# aes register map
Vendor: Texas Instruments
Peripheral module from a debugger description file (folder cc32).
Registers are 32-bit, access not given, no defined reset value unless marked. A register's access mark holds for its fields unless they carry their own. Offsets are as the file gives them; lines under a group give offsets from that group; [hi:lo] are bit positions; {n}, {i} and the like mark numbered series; 'fields as' and 'values as' point back to an identical list; <NAME> marks a mode.

## aes
0x00 KEY2_6 — XTS second key / CBC-MAC third key
0x04 KEY2_7 — XTS second key (MSW for 256-bit key) / CBC-MAC third key (MSW)
0x08 KEY2_4 — XTS / CCM second key / CBC-MAC third key (LSW)
0x0C KEY2_5 — XTS second key (MSW for 192-bit key) / CBC-MAC third key
0x10 KEY2_2 — XTS / CCM / CBC-MAC second key / Hash Key input
0x14 KEY2_3 — XTS second key (MSW for 128-bit key) + CCM/CBC-MAC second key (MSW) / Hash Key input (MSW)
0x18 KEY2_0 — XTS / CCM / CBC-MAC second key (LSW) / Hash Key input (LSW)
0x1C KEY2_1 — XTS / CCM / CBC-MAC second key / Hash Key input
0x20 KEY1_6 — Key (LSW for 256-bit key)
0x24 KEY1_7 — Key (MSW for 256-bit key)
0x28 KEY1_4 — Key (LSW for 192-bit key)
0x2C KEY1_5 — Key (MSW for 192-bit key)
0x30 KEY1_2 — Key
0x34 KEY1_3 — Key (MSW for 128-bit key)
0x38 KEY1_0 — Key (LSW for 128-bit key)
0x3C KEY1_1 — Key
0x40 IV_IN_0 — Initialization Vector input (LSW)
0x44 IV_IN_1 — Initialization vector input
0x48 IV_IN_2 — Initialization vector input
0x4C IV_IN_3 — Initialization Vector input (MSW)
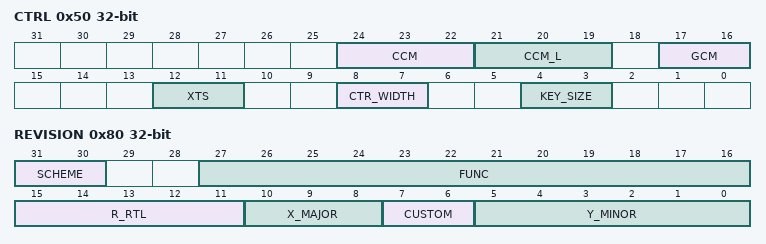
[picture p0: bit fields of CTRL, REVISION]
0x50 CTRL rw — register determines the mode of operation of the AES Engine
  [24:22] CCM — Defines M? that indicated the length of the authentication field for CCM operations; the authentication field length equals two times (the value of CCM-M plus one). Note that the AES Engine always returns a 128-bit authentication field@@ of which the M least significant bytes are valid. All values are supported.
  [21:19] CCM_L — Defines L? that indicated the width of the length field for CCM operations; the length field in bytes equals the value of CMM-L plus one. Supported values for L are (programmed value): 2 (1)@@ 4 (3) and 8 (7).
  [17:16] GCM — AES-GCM mode is selected.this is a combined mode@@ using the Galois field multiplier GF(2^128) for authentication and AES-CTR mode for encryption@@ the bits specify the GCM mode. 0x0 No operation 0x1 GHASH with H loaded and Y0-encrypted forced to zero 0x2 GHASH with H loaded and Y0-encrypted calculated internally 0x3 Autonomous GHASH (both H and Y0-encrypted calculated internally)
  [12:11] XTS — AES-XTS operation is selected; the bits specify the XTS mode.01 = Previous/intermediate tweak value and j loaded (value is loaded via IV@@ j is loaded via the AAD length register) 0x0 No operation 0x1 Previous/intermediate tweak value and j loaded (value is loaded via IV@@ j is loaded via the AAD length register) 0x2 Key2@@ i and j loaded (i is loaded via IV@@ j is loaded via the AAD length register) 0x3 Key2 and i loaded@@ j=0 (i is loaded via IV)
  [8:7] CTR_WIDTH — Specifies the counter width for AES-CTR mode 0x0 Counter is 32 bits 0x1 Counter is 64 bits 0x2 Counter is 128 bits 0x3 Counter is 192 bits
  [4:3] KEY_SIZE — key size 0x0 reserved 0x1 Key is 128 bits. 0x2 Key is 192 bits 0x3 Key is 256
0x54 C_LENGTH_0 — Crypto data length registers (LSW and MSW) store the cryptographic data length in bytes for all modes. Once processing with this context is started@@ this length decrements to zero. Data lengths up to (2^61 1) bytes are allowed. For GCM@@ any value up to 2^36 - 32 bytes can be used. This is because a 32-bit counter mode is used; the maximum number of 128-bit blocks is 2^32 2@@ resulting in a maximum number of bytes of 2^36 - 32. A write to this register triggers the engine to start using this context. This is valid for all modes except GCM and CCM. Note that for the combined modes@@ this length does not include the authentication only data; the authentication length is specified in the AES_AUTH_LENGTH register below. All modes must have a length > 0. For the combined modes@@ it is allowed to have one of the lengths equal to zero. For the basic encryption modes (ECB/CBC/CTR/ICM/CFB128) it is allowed to program zero to the length field; in that case the length is assumed infinite. All data must be byte (8-bit) aligned; bit aligned data streams are not supported by the AES Engine. For a Host read operation@@ these registers return all-zeroes.
0x58 C_LENGTH_1 rw — Crypto data length registers (LSW and MSW) store the cryptographic data length in bytes for all modes. Once processing with this context is started@@ this length decrements to zero. Data lengths up to (2^61 1) bytes are allowed. For GCM@@ any value up to 2^36 - 32 bytes can be used. This is because a 32-bit counter mode is used; the maximum number of 128-bit blocks is 2^32 2@@ resulting in a maximum number of bytes of 2^36 - 32. A write to this register triggers the engine to start using this context. This is valid for all modes except GCM and CCM. Note that for the combined modes@@ this length does not include the authentication only data; the authentication length is specified in the AES_AUTH_LENGTH register below. All modes must have a length > 0. For the combined modes@@ it is allowed to have one of the lengths equal to zero. For the basic encryption modes (ECB/CBC/CTR/ICM/CFB128) it is allowed to program zero to the length field; in that case the length is assumed infinite. All data must be byte (8-bit) aligned; bit aligned data streams are not supported by the AES Engine. For a Host read operation@@ these registers return all-zeroes.
  [28:0] LENGTH — Data length (MSW) length registers (LSW and MSW) store the cryptographic data length in bytes for all modes. Once processing with this context is started@@ this length decrements to zero. Data lengths up to (2^61 1) bytes are allowed. For GCM@@ any value up to 2^36 - 32 bytes can be used. This is because a 32-bit counter mode is used; the maximum number of 128-bit blocks is 2^32 2@@ resulting in a maximum number of bytes of 2^36 - 32. A write to this register triggers the engine to start using this context. This is valid for all modes except GCM and CCM. Note that for the combined modes@@ this length does not include the authentication only data; the authentication length is specified in the AES_AUTH_LENGTH register below. All modes must have a length > 0. For the combined modes@@ it is allowed to have one of the lengths equal to zero. For the basic encryption modes (ECB/CBC/CTR/ICM/CFB128) it is allowed to program zero to the length field; in that case the length is assumed infinite. All data must be byte (8-bit) aligned; bit aligned data streams are not supported by the AES Engine. For a Host read operation@@ these registers return all-zeroes.
0x5C AUTH_LENGTH — AAD data length. The authentication length register store the authentication data length in bytes for combined modes only (GCM or CCM) Supported AAD-lengths for CCM are from 0 to (2^16 - 2^8) bytes. For GCM any value up to (2^32 - 1) bytes can be used. Once processing with this context is started@@ this length decrements to zero. A write to this register triggers the engine to start using this context for GCM and CCM. For XTS this register is optionally used to load j. Loading of j is only required if j != 0. j is a 28-bit value and must be written to bits [31-4] of this register. j represents the sequential number of the 128-bit block inside the data unit. For the first block in a unit@@ this value is zero. It is not required to provide a j for each new data block within a unit. Note that it is possible to start with a j unequal to zero; refer to Table 4 for more details. For a Host read operation@@ these registers return all-zeroes.
0x60 DATA_IN_0 — Data register to read and write plaintext/ciphertext (MSW)
0x64 DATA_IN_1 — Data register to read and write plaintext/ciphertext
0x68 DATA_IN_2 — Data register to read and write plaintext/ciphertext
0x6C DATA_IN_3 — Data register to read and write plaintext/ciphertext (LSW)
{0x70+4i} TAG_OUT_{i} (i=0..3)
0x80 REVISION rw — Register AES_REVISION
  [31:30] SCHEME
  [27:16] FUNC — Function indicates a software compatible module family. If there is no level of software compatibility a new Func number (and hence REVISION) should be assigned.
  [15:11] R_RTL — RTL Version (R)@@ maintained by IP design owner. RTL follows a numbering such as X.Y.R.Z which are explained in this table. R changes ONLY when: (1) PDS uploads occur which may have been due to spec changes (2) Bug fixes occur (3) Resets to '0' when X or Y changes. Design team has an internal 'Z' (customer invisible) number which increments on every drop that happens due to DV and RTL updates. Z resets to 0 when R increments.
  [10:8] X_MAJOR — Major Revision (X)@@ maintained by IP specification owner. X changes ONLY when: (1) There is a major feature addition. An example would be adding Master Mode to Utopia Level2. The Func field (or Class/Type in old PID format) will remain the same. X does NOT change due to: (1) Bug fixes (2) Change in feature parameters.
  [7:6] CUSTOM
  [5:0] Y_MINOR — Minor Revision (Y)@@ maintained by IP specification owner. Y changes ONLY when: (1) Features are scaled (up or down). Flexibility exists in that this feature scalability may either be represented in the Y change or a specific register in the IP that indicates which features are exactly available. (2) When feature creeps from Is-Not list to Is list. But this may not be the case once it sees silicon; in which case X will change. Y does NOT change due to: (1) Bug fixes (2) Typos or clarifications (3) major functional/feature change/addition/deletion. Instead these changes may be reflected via R@@ S@@ X as applicable. Spec owner maintains a customer-invisible number 'S' which changes due to: (1) Typos/clarifications (2) Bug documentation. Note that this bug is not due to a spec change but due to implementation. Nevertheless@@ the spec tracks the IP bugs. An RTL release (say for silicon PG1.1) that occurs due to bug fix should document the corresponding spec number (X.Y.S) in its release notes.
0x84 SYSCONFIG — Register AES_SYSCONFIG.This register configures the DMA signals and controls the IDLE and reset logic
0x88 SYSSTATUS
0x8C IRQSTATUS — This register indicates the interrupt status. If one of the interrupt bits is set the interrupt output will be asserted
0x90 IRQENABLE — This register contains an enable bit for each unique interrupt generated by the module. It matches the layout of AES_IRQSTATUS register. An interrupt is enabled when the bit in this register is set to 1. An interrupt that is enabled is propagated to the SINTREQUEST_x output. All interrupts need to be enabled explicitly by writing this register. ****************************************************************************
